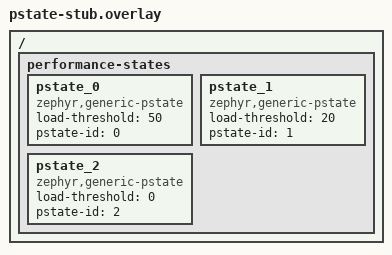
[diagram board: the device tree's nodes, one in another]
/*
 * Copyright (c) 2025 Intel Corporation
 *
 * SPDX-License-Identifier: Apache-2.0
 */

/ {
	performance-states {
		pstate_0: pstate_0 {
			compatible = "zephyr,generic-pstate";
			load-threshold = <50>;
			pstate-id = <0>;
		};
		pstate_1: pstate_1 {
			compatible = "zephyr,generic-pstate";
			load-threshold = <20>;
			pstate-id = <1>;
		};
		pstate_2: pstate_2 {
			compatible = "zephyr,generic-pstate";
			load-threshold = <0>;
			pstate-id = <2>;
		};
	};
};
